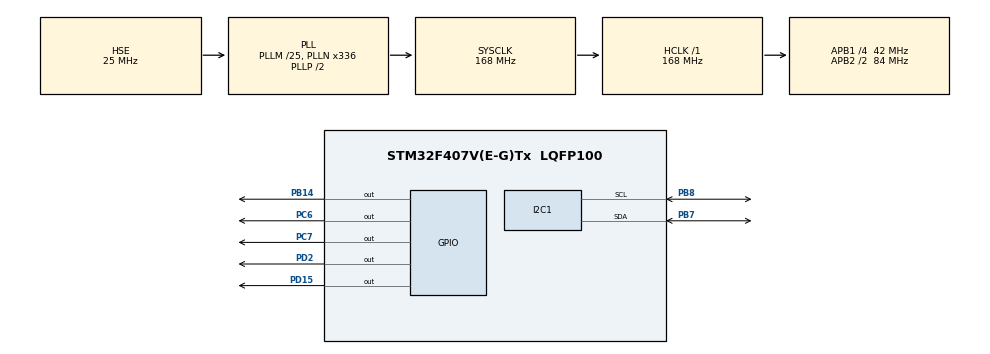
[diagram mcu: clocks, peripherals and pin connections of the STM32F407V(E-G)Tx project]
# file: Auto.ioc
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Mcu.Family=STM32F4
Mcu.Name=STM32F407V(E-G)Tx
Mcu.Package=LQFP100
NVIC.I2C1_ER_IRQn=true\:0\:0\:false\:false\:true
NVIC.I2C1_EV_IRQn=true\:0\:0\:false\:false\:true
NVIC.PriorityGroup=NVIC_PRIORITYGROUP_4
PA13.Mode=JTAG_5_pins
PA13.Signal=SYS_JTMS-SWDIO
PA14.Mode=JTAG_5_pins
PA14.Signal=SYS_JTCK-SWCLK
PA15.Mode=JTAG_5_pins
PA15.Signal=SYS_JTDI
PB14.PinState=GPIO_PIN_SET
PB14.Signal=GPIO_Output
PB3.Mode=JTAG_5_pins
PB3.Signal=SYS_JTDO-SWO
PB4.Mode=JTAG_5_pins
PB4.Signal=SYS_JTRST
PB7.Mode=I2C
PB7.Signal=I2C1_SDA
PB8.Mode=I2C
PB8.Signal=I2C1_SCL
PC6.GPIO_PuPd=GPIO_NOPULL
PC6.PinState=GPIO_PIN_SET
PC6.Signal=GPIO_Output
PC7.GPIO_PuPd=GPIO_NOPULL
PC7.PinState=GPIO_PIN_SET
PC7.Signal=GPIO_Output
PD15.GPIO_PuPd=GPIO_NOPULL
PD15.PinState=GPIO_PIN_SET
PD15.Signal=GPIO_Output
PD2.GPIO_PuPd=GPIO_NOPULL
PD2.PinState=GPIO_PIN_SET
PD2.Signal=GPIO_Output
PH0-OSC_IN.Mode=HSE-External-Oscillator
PH0-OSC_IN.Signal=RCC_OSC_IN
PH1-OSC_OUT.Mode=HSE-External-Oscillator
PH1-OSC_OUT.Signal=RCC_OSC_OUT
ProjectManager.HeapSize=0x200
ProjectManager.StackSize=0x400
ProjectManager.TargetToolchain=EWARM
RCC.48MHZClocksFreq_Value=84000000
RCC.AHBFreq_Value=168000000
RCC.APB1CLKDivider=RCC_HCLK_DIV4
RCC.APB1Freq_Value=42000000
RCC.APB1TimFreq_Value=84000000
RCC.APB2CLKDivider=RCC_HCLK_DIV2
RCC.APB2Freq_Value=84000000
RCC.APB2TimFreq_Value=168000000
RCC.CortexFreq_Value=168000000
RCC.HCLKFreq_Value=168000000
RCC.HSE_VALUE=25000000
RCC.HSI_VALUE=16000000
RCC.LSE_VALUE=32768
RCC.PLLM=25
RCC.PLLN=336
RCC.PLLSourceVirtual=RCC_PLLSOURCE_HSE
RCC.SYSCLKFreq_VALUE=168000000
RCC.SYSCLKSource=RCC_SYSCLKSOURCE_PLLCLK
RCC.VCOOutputFreq_Value=336000000
board=Auto

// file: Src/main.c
/**
  ******************************************************************************
  * File Name          : main.c
  * Description        : Main program body
  ******************************************************************************
  ** This notice applies to any and all portions of this file
  * that are not between comment pairs USER CODE BEGIN and
  * USER CODE END. Other portions of this file, whether
  * inserted by the user or by software development tools
  * are owned by their respective copyright owners.
  *
  * COPYRIGHT(c) 2017 STMicroelectronics
  *
  * Redistribution and use in source and binary forms, with or without modification,
  * are permitted provided that the following conditions are met:
  *   1. Redistributions of source code must retain the above copyright notice,
  *      this list of conditions and the following disclaimer.
  *   2. Redistributions in binary form must reproduce the above copyright notice,
  *      this list of conditions and the following disclaimer in the documentation
  *      and/or other materials provided with the distribution.
  *   3. Neither the name of STMicroelectronics nor the names of its contributors
  *      may be used to endorse or promote products derived from this software
  *      without specific prior written permission.
  *
  * THIS SOFTWARE IS PROVIDED BY THE COPYRIGHT HOLDERS AND CONTRIBUTORS "AS IS"
  * AND ANY EXPRESS OR IMPLIED WARRANTIES, INCLUDING, BUT NOT LIMITED TO, THE
  * IMPLIED WARRANTIES OF MERCHANTABILITY AND FITNESS FOR A PARTICULAR PURPOSE ARE
  * DISCLAIMED. IN NO EVENT SHALL THE COPYRIGHT HOLDER OR CONTRIBUTORS BE LIABLE
  * FOR ANY DIRECT, INDIRECT, INCIDENTAL, SPECIAL, EXEMPLARY, OR CONSEQUENTIAL
  * DAMAGES (INCLUDING, BUT NOT LIMITED TO, PROCUREMENT OF SUBSTITUTE GOODS OR
  * SERVICES; LOSS OF USE, DATA, OR PROFITS; OR BUSINESS INTERRUPTION) HOWEVER
  * CAUSED AND ON ANY THEORY OF LIABILITY, WHETHER IN CONTRACT, STRICT LIABILITY,
  * OR TORT (INCLUDING NEGLIGENCE OR OTHERWISE) ARISING IN ANY WAY OUT OF THE USE
  * OF THIS SOFTWARE, EVEN IF ADVISED OF THE POSSIBILITY OF SUCH DAMAGE.
  *
  ******************************************************************************
  */
#include "main.h"
#include "stm32f4xx_hal.h"

I2C_HandleTypeDef hi2c1;

/* USER CODE BEGIN PV */
/* Private variables ---------------------------------------------------------*/

/* USER CODE END PV */

void SystemClock_Config(void);
static void MX_GPIO_Init(void);
static void MX_I2C1_Init(void);

/* USER CODE BEGIN PFP */
/* Private function prototypes -----------------------------------------------*/

/* USER CODE END PFP */

int main(void)
{

  /* MCU Configuration----------------------------------------------------------*/

  /* Reset of all peripherals, Initializes the Flash interface and the Systick. */
  HAL_Init();

  /* Configure the system clock */
  SystemClock_Config();

  /* Initialize all configured peripherals */
  MX_GPIO_Init();
  MX_I2C1_Init();

  /* USER CODE BEGIN 2 */
    int d = 0;
    uint32_t i = 0;
    HAL_StatusTypeDef stat;
    HAL_I2C_StateTypeDef i2c_state;
    uint8_t data_t[2]={0x0F};
    uint8_t data_r[2]={0};

  /* USER CODE END 2 */

  /* Infinite loop */
  /* USER CODE BEGIN WHILE */

#define ADRR 0x3D
    //stat = HAL_I2C_Master_Receive(&hi2c1, 0xA0, uint8_t *pData, uint16_t Size, 100);
  while (1)
  {
  /* USER CODE END WHILE */

  /* USER CODE BEGIN 3 */
    for(i = 0; i<255;i++)
    {
        stat =  HAL_I2C_Mem_Read(&hi2c1, i, 0x0F, 1, data_r, 1, 10);
        //stat =  HAL_I2C_Mem_Read(&hi2c1, 0x3C, 0x0F, 1, data_r, 1, 10);
        //stat =  HAL_I2C_Mem_Read(&hi2c1, 0x3B, 0x0F, 1, data_r, 1, 10);
        //stat =  HAL_I2C_Mem_Read(&hi2c1, 0x3D, 0x0F, 1, data_r, 1, 10);//HAL_I2C_IsDeviceReady(I2C_HandleTypeDef *hi2c, uint16_t DevAddress, uint32_t Trials, uint32_t Timeout)
        if(stat==HAL_OK)
            d++;

    }
  }
  /* USER CODE END 3 */

}

/** System Clock Configuration
*/
void SystemClock_Config(void)
{

  RCC_OscInitTypeDef RCC_OscInitStruct;
  RCC_ClkInitTypeDef RCC_ClkInitStruct;

    /**Configure the main internal regulator output voltage
    */
  __HAL_RCC_PWR_CLK_ENABLE();

  __HAL_PWR_VOLTAGESCALING_CONFIG(PWR_REGULATOR_VOLTAGE_SCALE1);

    /**Initializes the CPU, AHB and APB busses clocks
    */
  RCC_OscInitStruct.OscillatorType = RCC_OSCILLATORTYPE_HSE;
  RCC_OscInitStruct.HSEState = RCC_HSE_ON;
  RCC_OscInitStruct.PLL.PLLState = RCC_PLL_ON;
  RCC_OscInitStruct.PLL.PLLSource = RCC_PLLSOURCE_HSE;
  RCC_OscInitStruct.PLL.PLLM = 25;
  RCC_OscInitStruct.PLL.PLLN = 336;
  RCC_OscInitStruct.PLL.PLLP = RCC_PLLP_DIV2;
  RCC_OscInitStruct.PLL.PLLQ = 4;
  if (HAL_RCC_OscConfig(&RCC_OscInitStruct) != HAL_OK)
  {
    _Error_Handler(__FILE__, __LINE__);
  }

    /**Initializes the CPU, AHB and APB busses clocks
    */
  RCC_ClkInitStruct.ClockType = RCC_CLOCKTYPE_HCLK|RCC_CLOCKTYPE_SYSCLK
                              |RCC_CLOCKTYPE_PCLK1|RCC_CLOCKTYPE_PCLK2;
  RCC_ClkInitStruct.SYSCLKSource = RCC_SYSCLKSOURCE_PLLCLK;
  RCC_ClkInitStruct.AHBCLKDivider = RCC_SYSCLK_DIV1;
  RCC_ClkInitStruct.APB1CLKDivider = RCC_HCLK_DIV4;
  RCC_ClkInitStruct.APB2CLKDivider = RCC_HCLK_DIV2;

  if (HAL_RCC_ClockConfig(&RCC_ClkInitStruct, FLASH_LATENCY_5) != HAL_OK)
  {
    _Error_Handler(__FILE__, __LINE__);
  }

    /**Configure the Systick interrupt time
    */
  HAL_SYSTICK_Config(HAL_RCC_GetHCLKFreq()/1000);

    /**Configure the Systick
    */
  HAL_SYSTICK_CLKSourceConfig(SYSTICK_CLKSOURCE_HCLK);

  /* SysTick_IRQn interrupt configuration */
  HAL_NVIC_SetPriority(SysTick_IRQn, 0, 0);
}

/* I2C1 init function */
static void MX_I2C1_Init(void)
{

  hi2c1.Instance = I2C1;
  hi2c1.Init.ClockSpeed = 100000;
  hi2c1.Init.DutyCycle = I2C_DUTYCYCLE_2;
  hi2c1.Init.OwnAddress1 = 0;
  hi2c1.Init.AddressingMode = I2C_ADDRESSINGMODE_7BIT;
  hi2c1.Init.DualAddressMode = I2C_DUALADDRESS_DISABLE;
  hi2c1.Init.OwnAddress2 = 0;
  hi2c1.Init.GeneralCallMode = I2C_GENERALCALL_DISABLE;
  hi2c1.Init.NoStretchMode = I2C_NOSTRETCH_DISABLE;
  if (HAL_I2C_Init(&hi2c1) != HAL_OK)
  {
    _Error_Handler(__FILE__, __LINE__);
  }

}

/** Configure pins as
        * Analog
        * Input
        * Output
        * EVENT_OUT
        * EXTI
*/
static void MX_GPIO_Init(void)
{

  GPIO_InitTypeDef GPIO_InitStruct;

  /* GPIO Ports Clock Enable */
  __HAL_RCC_GPIOH_CLK_ENABLE();
  __HAL_RCC_GPIOB_CLK_ENABLE();
  __HAL_RCC_GPIOD_CLK_ENABLE();
  __HAL_RCC_GPIOC_CLK_ENABLE();
  __HAL_RCC_GPIOA_CLK_ENABLE();

  /*Configure GPIO pin Output Level */
  HAL_GPIO_WritePin(GPIOB, GPIO_PIN_14, GPIO_PIN_SET);

  /*Configure GPIO pin Output Level */
  HAL_GPIO_WritePin(GPIOD, GPIO_PIN_15|GPIO_PIN_2, GPIO_PIN_SET);

  /*Configure GPIO pin Output Level */
  HAL_GPIO_WritePin(GPIOC, GPIO_PIN_6|GPIO_PIN_7, GPIO_PIN_SET);

  /*Configure GPIO pin : PB14 */
  GPIO_InitStruct.Pin = GPIO_PIN_14;
  GPIO_InitStruct.Mode = GPIO_MODE_OUTPUT_PP;
  GPIO_InitStruct.Pull = GPIO_NOPULL;
  GPIO_InitStruct.Speed = GPIO_SPEED_FREQ_LOW;
  HAL_GPIO_Init(GPIOB, &GPIO_InitStruct);

  /*Configure GPIO pins : PD15 PD2 */
  GPIO_InitStruct.Pin = GPIO_PIN_15|GPIO_PIN_2;
  GPIO_InitStruct.Mode = GPIO_MODE_OUTPUT_PP;
  GPIO_InitStruct.Pull = GPIO_NOPULL;
  GPIO_InitStruct.Speed = GPIO_SPEED_FREQ_LOW;
  HAL_GPIO_Init(GPIOD, &GPIO_InitStruct);

  /*Configure GPIO pins : PC6 PC7 */
  GPIO_InitStruct.Pin = GPIO_PIN_6|GPIO_PIN_7;
  GPIO_InitStruct.Mode = GPIO_MODE_OUTPUT_PP;
  GPIO_InitStruct.Pull = GPIO_NOPULL;
  GPIO_InitStruct.Speed = GPIO_SPEED_FREQ_LOW;
  HAL_GPIO_Init(GPIOC, &GPIO_InitStruct);

}

void _Error_Handler(char * file, int line)
{
  while(1)
  {
  }
}

/************************ (C) COPYRIGHT STMicroelectronics *****END OF FILE****/
